# M411_unitA register map
File version: 2.0.2.2
TOSHIBA Cortex-M4 MCU
Registers are 32-bit, read-write, reset 0x0 unless marked. A register's access mark holds for its fields unless they carry their own. Offsets are from the block's base; lines under a group give offsets from that group; [hi:lo] are bit positions; {n}, {i} and the like mark numbered series; 'fields as' and 'values as' point back to an identical list; <NAME> marks a mode.

## Memory map
0x4003C000 LCD size 0x48 — LCD Driver (LCD)
0x4003C480 AO blocks up to offset 0xF — Alyays On (AO)
0x40040000 SSP0 size 0x28 — Synchronous Serial Port (SSP)
0x40041000 SSP1 size 0x28
0x40042000 SSP2 size 0x28
0x40048000 UART blocks up to offset 0x4C — UART (Full UART)
0x4004C000 DMA blocks up to offset 0x50 — DMA Controller (DMA)
0x40050000 AD blocks up to offset 0x78 — 12bit A_D Converter (AD)
0x4008D000 T16A0 size 0x14 — 16-bit TimerA (T16A)
0x4008E000 T16A1 size 0x14
0x400A0000 I2C size 0x1C — I2C Bus Interface (I2C)
0x400B8000 INT size 0x58 — Interrupt Controller (INT)
0x400BC000 CPUIF size 0x18 — CPU Interface (CPUIF)
0x400C0000 PA blocks up to offset 0x3C — Port A (PA)
0x400C0100 PB blocks up to offset 0x3C — Port B (PB)
0x400C0200 PC blocks up to offset 0x3C — Port C (PC)
0x400C0300 PD blocks up to offset 0x3C — Port D (PD)
0x400C0400 PE blocks up to offset 0x3C — Port E (PE)
0x400C0500 PF blocks up to offset 0x3C — Port F (PF)
0x400C0600 PG blocks up to offset 0x3C — Port G (PG)
0x400C4000 TB0 size 0x30 — 16-bit Timer_Event Counter (TB)
0x400C4100 TB1 size 0x30
0x400C4200 TB2 size 0x30
0x400CC000 RTC blocks up to offset 0x26 — Real Time Clock (RTC)
0x400E1000 SC0 size 0x34 — SIO_UART (SC)
0x400E1100 SC1 size 0x34
0x400F2000 WD size 0xC — Watchdog Timer (WD)
0x400F3000 CG size 0x30 — Clock Control (CG)
0x5DFF0000 FC blocks up to offset 0x15C — Flash Control (FC)

## LCD — LCD Driver (LCD)
Base 0x4003C000
0x00 EN — Enable Register
  [0] LEDE
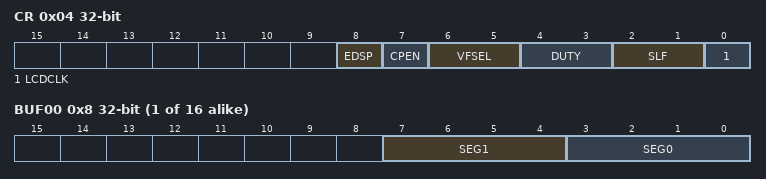
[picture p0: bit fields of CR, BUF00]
0x04 CR — Control Register
  [8] EDSP, [7] CPEN, [6:5] VFSEL, [4:3] DUTY, [2:1] SLF, [0] LCDCLK
{0x8+4i} BUF{i:02} (i=0..15) — Buffer Register {i:02}
  [7:4] SEG{2i+1}, [3:0] SEG{2i}

## AO — Alyays On (AO)
Base 0x4003C480
0x00 CR0 8-bit — Display Selection Register
  [0] MODE
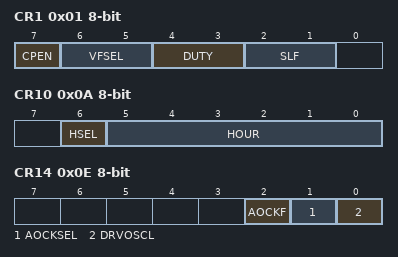
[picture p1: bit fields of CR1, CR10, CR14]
0x01 CR1 8-bit (reset mask 0x1) — Configuration Register
  [7] CPEN, [6:5] VFSEL, [4:3] DUTY, [2:1] SLF
0x02 CR2 8-bit (reset mask 0x80) — Display Screen Register
  [6:0] DATANUM
0x03 CR3 8-bit (reset mask 0x80) — Total Display Time Register
  [6:0] TIMEOUT
0x04 CR4 8-bit (reset mask 0xE0) — Screen Switch Time Register
  [4:0] UPDATE
0x05 CR5 8-bit reset 0xF — Response Count Register
  [3:0] DISPNUM
0x06 CR6 8-bit — Display Reponse Register
  [3:0] RESPNUM
0x08 CR8 8-bit ro (reset mask 0x80) — Display Start Time Register (Second)
  [6:0] SEC
0x09 CR9 8-bit ro (reset mask 0x80) — Display Start Time Register (Minutes)
  [6:0] MIN
0x0A CR10 8-bit ro (reset mask 0x80) — Display Start Time Register (Hour)
  [6] HSEL, [5:0] HOUR
0x0B CR11 8-bit ro (reset mask 0xC0) — Display Start Time Register (Day)
  [5:0] DAY
0x0C CR12 8-bit ro (reset mask 0xE0) — Display Start Time Register (Month)
  [4:0] MONTH
0x0D CR13 8-bit ro reset not defined — Display Start Time Register (Year)
  [7:0] YEAR
0x0E CR14 8-bit — Low-speec Clock Control Register
  [2] AOCKF ro, [1] AOCKSEL, [0] DRVOSCL

## SSP0 — Synchronous Serial Port (SSP)
Base 0x40040000
Same registers: SSP1 0x40041000, SSP2 0x40042000
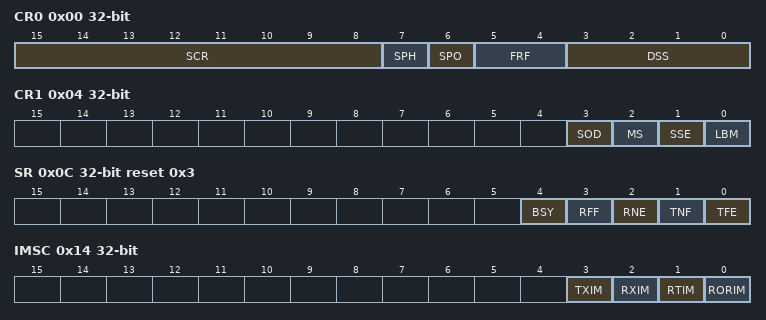
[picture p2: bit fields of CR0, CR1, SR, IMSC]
0x00 CR0 — SSP Control Register 0
  [15:8] SCR, [7] SPH, [6] SPO, [5:4] FRF, [3:0] DSS
0x04 CR1 — SSP Control Register 1
  [3] SOD, [2] MS, [1] SSE, [0] LBM
0x08 DR — SSP Data Register
  [15:0] DATA
0x0C SR ro reset 0x3 — SSP Status Register
  [4] BSY, [3] RFF, [2] RNE, [1] TNF, [0] TFE
0x10 CPSR — SSP Clock Prescaler Register
  [7:0] CPSDVSR
0x14 IMSC — SSP Interrupt Mask Set and Clear Register
  [3] TXIM, [2] RXIM, [1] RTIM, [0] RORIM
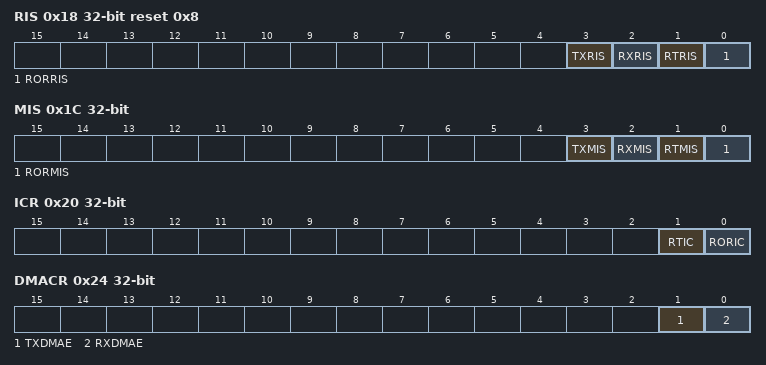
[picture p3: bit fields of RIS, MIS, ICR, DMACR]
0x18 RIS ro reset 0x8 — SSP Raw Interrupt Status Register
  [3] TXRIS, [2] RXRIS, [1] RTRIS, [0] RORRIS
0x1C MIS ro — SSP Masked Interrupt Status Register
  [3] TXMIS, [2] RXMIS, [1] RTMIS, [0] RORMIS
0x20 ICR wo reset not defined — SSP Interrupt Clear Register
  [1] RTIC, [0] RORIC
0x24 DMACR — SSP DMA Control Register
  [1] TXDMAE, [0] RXDMAE
